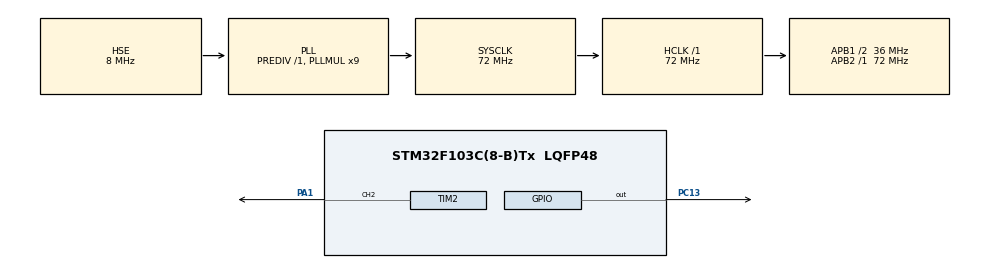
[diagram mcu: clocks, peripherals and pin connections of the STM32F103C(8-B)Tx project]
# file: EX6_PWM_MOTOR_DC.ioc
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Mcu.Family=STM32F1
Mcu.Name=STM32F103C(8-B)Tx
Mcu.Package=LQFP48
NVIC.PriorityGroup=NVIC_PRIORITYGROUP_4
NVIC.TIM2_IRQn=true\:0\:0\:false\:false\:true\:true\:true
PA1.Signal=S_TIM2_CH2
PA13.Mode=Serial_Wire
PA13.Signal=SYS_JTMS-SWDIO
PA14.Mode=Serial_Wire
PA14.Signal=SYS_JTCK-SWCLK
PC13-TAMPER-RTC.Signal=GPIO_Output
PD0-OSC_IN.Mode=HSE-External-Oscillator
PD0-OSC_IN.Signal=RCC_OSC_IN
PD1-OSC_OUT.Mode=HSE-External-Oscillator
PD1-OSC_OUT.Signal=RCC_OSC_OUT
ProjectManager.HeapSize=0x200
ProjectManager.StackSize=0x400
ProjectManager.TargetToolchain=STM32CubeIDE
RCC.AHBFreq_Value=72000000
RCC.APB1CLKDivider=RCC_HCLK_DIV2
RCC.APB1Freq_Value=36000000
RCC.APB1TimFreq_Value=72000000
RCC.APB2Freq_Value=72000000
RCC.APB2TimFreq_Value=72000000
RCC.HCLKFreq_Value=72000000
RCC.PLLMUL=RCC_PLL_MUL9
RCC.PLLSourceVirtual=RCC_PLLSOURCE_HSE
RCC.SYSCLKFreq_VALUE=72000000
RCC.SYSCLKSource=RCC_SYSCLKSOURCE_PLLCLK
RCC.USBFreq_Value=72000000
SH.S_TIM2_CH2.0=TIM2_CH2,PWM Generation2 CH2
TIM2.Channel-PWM\ Generation2\ CH2=TIM_CHANNEL_2
TIM2.Period=0xffff-1
TIM2.Prescaler=72-1
VP_TIM2_VS_ClockSourceINT.Mode=Internal
board=custom

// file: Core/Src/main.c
/* USER CODE BEGIN Header */
/**
  ******************************************************************************
  * @file           : main.c
  * @brief          : Main program body
  ******************************************************************************
  *						 EXEMPLO DE PWM MOTOR DC (stm32f103c8)
  ******************************************************************************
  * Aluno:        Ruan Robert Bispo dos Santos                            2019.2
  * Orientadores: Lucas Molina e Elyson Adan Nunes Carvalho
  *
  * CODIGO DA PLACA DE INTERFACE DO MATLAB COM O STM32F103C8
  *
  * @Resumo: Código teste para a função de pwm. Nesse exemplo é
  * 		 implementada uma função que usa o timer para fazer o PWM
  * 		 generalizado para um motor DC, assim é possível variar a
  * 		 frequência para testes e o duty cycle como requerido.
  * 		 Nesse exemplo é utilizado o LED embarcado como exemplo
  *
  * 		 A variação de frequência pode ser realizada alterando o ARR e PR.
  * 		  			  f = clock/( (ARR + 1)*(PR + 1) )
  *
  * 		 A variação de duty cycle pode ser realzada alterando o CCR com o duty
  * 		 			      CCRx = (duty*ARR)/100
  *
  *
  * @Configurações:
  *   		 Clock   - 72 MHz
  *
  * @Funções:
  * 		 TIM2_IRQHandler(void)    -   Interrupção de Timer 2
  * 		 Local de implementação da função: (src/stm32f1xx.it.c)
  *
  *
  ******************************************************************************
  * @attention
  *
  * <h2><center>&copy; Copyright (c) 2020 STMicroelectronics.
  * All rights reserved.</center></h2>
  *
  * This software component is licensed by ST under BSD 3-Clause license,
  * the "License"; You may not use this file except in compliance with the
  * License. You may obtain a copy of the License at:
  *                        opensource.org/licenses/BSD-3-Clause
  *
  ******************************************************************************
  */
/* USER CODE END Header */

#include "main.h"

TIM_HandleTypeDef htim2;

void SystemClock_Config(void);
static void MX_GPIO_Init(void);
static void MX_TIM2_Init(void);

int main(void)
{

  /* MCU Configuration--------------------------------------------------------*/

  /* Reset of all peripherals, Initializes the Flash interface and the Systick. */
  HAL_Init();

  /* Configure the system clock */
  SystemClock_Config();

  /* Initialize all configured peripherals */
  MX_GPIO_Init();
  MX_TIM2_Init();
  /* USER CODE BEGIN 2 */

  //////////////////  INICIALIZAÇÃO DO PWM  ////////////////////////

  	//Exemplo de motor DC - duty fixo e frequência variando
  	HAL_TIM_PWM_Start(&htim2, TIM_CHANNEL_2); // inicializa o PWM
  	HAL_TIM_Base_Start_IT(&htim2);            // inicializa interrupção por Timer
  	int duty_T2 = 50; // variável de controle do duty do PWM do timer 2
  	__HAL_TIM_SET_COUNTER(&htim2,0);          // inicializa o contador para 0

  	htim2.Instance->CCR2 = (duty_T2*htim2.Init.Period)/100; //atribui o valor de duty ao PWM, usar sempre que atualizar o duty em codigo

  /* USER CODE END 2 */

  /* Infinite loop */
  /* USER CODE BEGIN WHILE */
  while (1)
  {
	  ////////////////////////////////////////////////
	  ////////////////////////////////////////////////
	  // CÓDIGO IMPLEMENTADO NA FUNÇÃO DE INTERRUPÇÃO:
	  // 	TIM2_IRQHandler(void)
	  // 	Arquivo: src/stm32f1xx.it.c
	  ////////////////////////////////////////////////
	  ////////////////////////////////////////////////

    /* USER CODE END WHILE */

  }
}

void SystemClock_Config(void)
{
  RCC_OscInitTypeDef RCC_OscInitStruct = {0};
  RCC_ClkInitTypeDef RCC_ClkInitStruct = {0};

  /** Initializes the CPU, AHB and APB busses clocks
  */
  RCC_OscInitStruct.OscillatorType = RCC_OSCILLATORTYPE_HSE;
  RCC_OscInitStruct.HSEState = RCC_HSE_ON;
  RCC_OscInitStruct.HSEPredivValue = RCC_HSE_PREDIV_DIV1;
  RCC_OscInitStruct.HSIState = RCC_HSI_ON;
  RCC_OscInitStruct.PLL.PLLState = RCC_PLL_ON;
  RCC_OscInitStruct.PLL.PLLSource = RCC_PLLSOURCE_HSE;
  RCC_OscInitStruct.PLL.PLLMUL = RCC_PLL_MUL9;
  if (HAL_RCC_OscConfig(&RCC_OscInitStruct) != HAL_OK)
  {
    Error_Handler();
  }
  /** Initializes the CPU, AHB and APB busses clocks
  */
  RCC_ClkInitStruct.ClockType = RCC_CLOCKTYPE_HCLK|RCC_CLOCKTYPE_SYSCLK
                              |RCC_CLOCKTYPE_PCLK1|RCC_CLOCKTYPE_PCLK2;
  RCC_ClkInitStruct.SYSCLKSource = RCC_SYSCLKSOURCE_PLLCLK;
  RCC_ClkInitStruct.AHBCLKDivider = RCC_SYSCLK_DIV1;
  RCC_ClkInitStruct.APB1CLKDivider = RCC_HCLK_DIV2;
  RCC_ClkInitStruct.APB2CLKDivider = RCC_HCLK_DIV1;

  if (HAL_RCC_ClockConfig(&RCC_ClkInitStruct, FLASH_LATENCY_2) != HAL_OK)
  {
    Error_Handler();
  }
}

static void MX_TIM2_Init(void)
{

  TIM_ClockConfigTypeDef sClockSourceConfig = {0};
  TIM_MasterConfigTypeDef sMasterConfig = {0};
  TIM_OC_InitTypeDef sConfigOC = {0};

  htim2.Instance = TIM2;
  htim2.Init.Prescaler = 72-1;
  htim2.Init.CounterMode = TIM_COUNTERMODE_UP;
  htim2.Init.Period = 0xffff-1;
  htim2.Init.ClockDivision = TIM_CLOCKDIVISION_DIV1;
  htim2.Init.AutoReloadPreload = TIM_AUTORELOAD_PRELOAD_DISABLE;
  if (HAL_TIM_Base_Init(&htim2) != HAL_OK)
  {
    Error_Handler();
  }
  sClockSourceConfig.ClockSource = TIM_CLOCKSOURCE_INTERNAL;
  if (HAL_TIM_ConfigClockSource(&htim2, &sClockSourceConfig) != HAL_OK)
  {
    Error_Handler();
  }
  if (HAL_TIM_PWM_Init(&htim2) != HAL_OK)
  {
    Error_Handler();
  }
  sMasterConfig.MasterOutputTrigger = TIM_TRGO_RESET;
  sMasterConfig.MasterSlaveMode = TIM_MASTERSLAVEMODE_DISABLE;
  if (HAL_TIMEx_MasterConfigSynchronization(&htim2, &sMasterConfig) != HAL_OK)
  {
    Error_Handler();
  }
  sConfigOC.OCMode = TIM_OCMODE_PWM1;
  sConfigOC.Pulse = 0;
  sConfigOC.OCPolarity = TIM_OCPOLARITY_HIGH;
  sConfigOC.OCFastMode = TIM_OCFAST_DISABLE;
  if (HAL_TIM_PWM_ConfigChannel(&htim2, &sConfigOC, TIM_CHANNEL_2) != HAL_OK)
  {
    Error_Handler();
  }
  HAL_TIM_MspPostInit(&htim2);

}

static void MX_GPIO_Init(void)
{
  GPIO_InitTypeDef GPIO_InitStruct = {0};

  /* GPIO Ports Clock Enable */
  __HAL_RCC_GPIOC_CLK_ENABLE();
  __HAL_RCC_GPIOD_CLK_ENABLE();
  __HAL_RCC_GPIOA_CLK_ENABLE();

  /*Configure GPIO pin Output Level */
  HAL_GPIO_WritePin(GPIOC, GPIO_PIN_13, GPIO_PIN_RESET);

  /*Configure GPIO pin : PC13 */
  GPIO_InitStruct.Pin = GPIO_PIN_13;
  GPIO_InitStruct.Mode = GPIO_MODE_OUTPUT_PP;
  GPIO_InitStruct.Pull = GPIO_NOPULL;
  GPIO_InitStruct.Speed = GPIO_SPEED_FREQ_LOW;
  HAL_GPIO_Init(GPIOC, &GPIO_InitStruct);

}

void Error_Handler(void)
{
}

/************************ (C) COPYRIGHT STMicroelectronics *****END OF FILE****/
